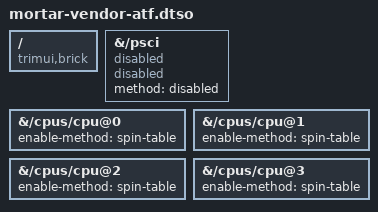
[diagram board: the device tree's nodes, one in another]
// SPDX-License-Identifier: (GPL-2.0+ OR MIT)
//
// Boot-chain compatibility overlay for sun50i-a133-trimui-brick.dtb
// (jkingston's mainline DTS) when booted through brittonr's chain:
//   vendor boot0 -> patched vendor ATF -> AArch32 shim -> RMR -> U-Boot
//
// After the RMR warm reset the vendor ATF only services SMCs from AArch32
// (EC=0x13); an AArch64 SMC (EC=0x17/0x26) faults, so the kernel's
// psci_probe() panics (see FINDINGS.md, 2026-02-26 11:49 onwards).
// Until the boot chain hands over a working PSCI implementation we run
// single-core, exactly as the Liontron overlay (trimui-brick.dtso) does.
//
// Unlike the Liontron overlay, this one does NOT touch the PMIC, MMC,
// pinctrl supplies or watchdog: the TrimUI DTS describes the real AXP2202
// and regulators, and the watchdog doubles as the restart handler when
// PSCI SYSTEM_RESET is unavailable.
//
// Uses target paths (&{/...}) rather than labels so it applies whether or
// not the base DTB was compiled with __symbols__ (-@).

/dts-v1/;
/plugin/;

// Must match the base DTB's compatible for NixOS' overlay application.
/ {
	compatible = "trimui,brick";
};

&{/psci} {
	compatible = "disabled";
	method = "disabled";
	status = "disabled";
};

&{/cpus/cpu@0} {
	enable-method = "spin-table";
};

&{/cpus/cpu@1} {
	enable-method = "spin-table";
};

&{/cpus/cpu@2} {
	enable-method = "spin-table";
};

&{/cpus/cpu@3} {
	enable-method = "spin-table";
};
